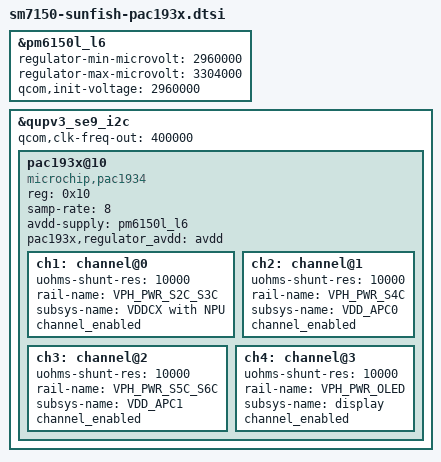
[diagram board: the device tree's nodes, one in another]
/* Copyright (c) 2018, The Linux Foundation. All rights reserved.
 *
 * This program is free software; you can redistribute it and/or modify
 * it under the terms of the GNU General Public License version 2 and
 * only version 2 as published by the Free Software Foundation.
 *
 * This program is distributed in the hope that it will be useful,
 * but WITHOUT ANY WARRANTY; without even the implied warranty of
 * MERCHANTABILITY or FITNESS FOR A PARTICULAR PURPOSE.  See the
 * GNU General Public License for more details.
 */
&pm6150l_l6 {
	regulator-min-microvolt = <2960000>;
	regulator-max-microvolt = <3304000>;
	qcom,init-voltage = <2960000>;
	status = "ok";
};

&qupv3_se9_i2c {
	status = "ok";
	qcom,clk-freq-out = <400000>;
	pac193x@10 {
		compatible = "microchip,pac1934";
		reg = <0x10>;
		samp-rate = <8>;
		status = "okay";
		avdd-supply = <&pm6150l_l6>;
		pac193x,regulator_avdd = "avdd";
		ch1: channel@0 {
		     uohms-shunt-res = <10000>;
		     rail-name = "VPH_PWR_S2C_S3C";
		     subsys-name = "VDDCX with NPU";
		     channel_enabled;
		};
		ch2: channel@1 {
		     uohms-shunt-res = <10000>;
		     rail-name = "VPH_PWR_S4C";
		     subsys-name = "VDD_APC0";
		     channel_enabled;
		};
		ch3: channel@2 {
		     uohms-shunt-res = <10000>;
		     rail-name = "VPH_PWR_S5C_S6C";
		     subsys-name = "VDD_APC1";
		     channel_enabled;
		};
		ch4: channel@3 {
		     uohms-shunt-res = <10000>;
		     rail-name = "VPH_PWR_OLED";
		     subsys-name = "display";
		     channel_enabled;
		};
	};
};
